VERSION ""

NS_ :

BS_:

BU_: DEVICE PC

BO_ 257 MA_THE_VA_TRANG_THAI: 6 DEVICE
 SG_ Ma_The_UID : 7|40@0+ (1,0) [0|0] "" PC
 SG_ Trang_Thai_Doc : 47|8@0+ (1,0) [0|1] "" PC

BO_ 258 BO_DEM: 4 DEVICE
 SG_ Dem_Hien_Tai : 7|16@0+ (1,0) [0|9999] "" PC
 SG_ Dem_Muc_Tieu : 23|16@0+ (1,0) [0|9999] "" PC

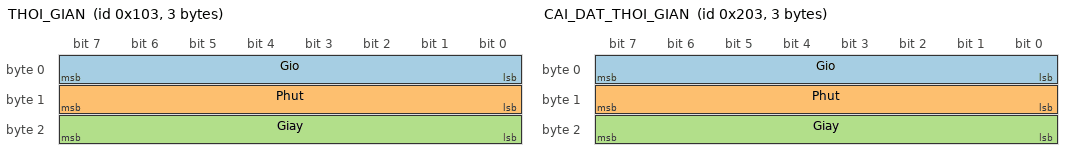
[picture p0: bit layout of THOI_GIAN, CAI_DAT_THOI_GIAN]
BO_ 259 THOI_GIAN: 3 DEVICE
 SG_ Gio : 7|8@0+ (1,0) [0|23] "" PC
 SG_ Phut : 15|8@0+ (1,0) [0|59] "" PC
 SG_ Giay : 23|8@0+ (1,0) [0|59] "" PC

BO_ 260 DU_LIEU_THE_P1: 8 DEVICE
 SG_ Du_Lieu_0_7 : 7|64@0+ (1,0) [0|0] "" PC

BO_ 261 DU_LIEU_THE_P2: 8 DEVICE
 SG_ Du_Lieu_8_15 : 7|64@0+ (1,0) [0|0] "" PC

BO_ 292 THONG_SO_CAM_BIEN: 8 DEVICE
 SG_ Tgian_Block_ms : 7|32@0+ (1,0) [0|0] "" PC
 SG_ Tgian_Gap_ms : 39|32@0+ (1,0) [0|0] "" PC

BO_ 293 THONG_SO_THE_SD: 4 DEVICE
 SG_ Tgian_Mount_ms : 7|32@0+ (1,0) [0|0] "" PC

BO_ 513 CAI_DAT_MUC_TIEU: 2 PC
 SG_ Muc_Tieu : 7|16@0+ (1,0) [0|9999] "" DEVICE

BO_ 514 CAI_DAT_DEM_HT: 2 PC
 SG_ Dem_Hien_Tai : 7|16@0+ (1,0) [0|9999] "" DEVICE

BO_ 515 CAI_DAT_THOI_GIAN: 3 PC
 SG_ Gio : 7|8@0+ (1,0) [0|23] "" DEVICE
 SG_ Phut : 15|8@0+ (1,0) [0|59] "" DEVICE
 SG_ Giay : 23|8@0+ (1,0) [0|59] "" DEVICE

BO_ 516 CAI_DAT_CN_THE: 1 PC
 SG_ Chuc_Nang : 7|8@0+ (1,0) [1|4] "" DEVICE

BO_ 517 QUAN_LY_THE: 7 PC
 SG_ Hanh_Dong : 7|8@0+ (1,0) [0|1] "" DEVICE
 SG_ Mat_Khau_Moi : 15|48@0+ (1,0) [0|0] "" DEVICE

BO_ 518 CAI_MAT_KHAU_TAM: 6 PC
 SG_ Mat_Khau_Tam : 7|48@0+ (1,0) [0|0] "" DEVICE

VAL_ 257 Trang_Thai_Doc 0 "Thanh Cong" 1 "That Bai" ;
VAL_ 516 Chuc_Nang 1 "Cong 1" 2 "Tru 1" 3 "Reset" 4 "Phat Nhac" ;
VAL_ 517 Hanh_Dong 0 "Xoa the" 1 "oi Key" ;
CM_ BO_ 257 "Ma the va Trang thai doc";
CM_ SG_ 257 Ma_The_UID "Ma UID cua the RFID";
CM_ SG_ 257 Trang_Thai_Doc "Trang thai doc the";

CM_ BO_ 258 "Bo dem san pham";
CM_ SG_ 258 Dem_Hien_Tai "So dem hien tai";
CM_ SG_ 258 Dem_Muc_Tieu "So dem muc tieu";

CM_ BO_ 259 "Thoi gian he thong";
CM_ SG_ 259 Gio "Gio";
CM_ SG_ 259 Phut "Phut";
CM_ SG_ 259 Giay "Giay";

CM_ BO_ 260 "Du lieu doc tu the (Phan 1)";
CM_ SG_ 260 Du_Lieu_0_7 "8 byte du lieu dau";

CM_ BO_ 261 "Du lieu doc tu the (Phan 2)";
CM_ SG_ 261 Du_Lieu_8_15 "8 byte du lieu sau";

CM_ BO_ 292 "Thong so chan doan cam bien";
CM_ SG_ 292 Tgian_Block_ms "Thoi gian bi che (ms)";
CM_ SG_ 292 Tgian_Gap_ms "Thoi gian ho (ms)";

CM_ BO_ 293 "Thong so chan doan the SD";
CM_ SG_ 293 Tgian_Mount_ms "Thoi gian Mount the (ms)";

CM_ BO_ 513 "Cai dat so dem muc tieu";
CM_ SG_ 513 Muc_Tieu "Gia tri muc tieu moi";

CM_ BO_ 514 "Cai dat so dem hien tai";
CM_ SG_ 514 Dem_Hien_Tai "Gia tri dem hien tai moi";

CM_ BO_ 515 "Cai dat thoi gian he thong";
CM_ SG_ 515 Gio "Gio moi";
CM_ SG_ 515 Phut "Phut moi";
CM_ SG_ 515 Giay "Giay moi";

CM_ BO_ 516 "Cai dat chuc nang the RFID";
CM_ SG_ 516 Chuc_Nang "Chuc nang gan cho the";

CM_ BO_ 517 "Xoa the hoac Doi mat khau";
CM_ SG_ 517 Hanh_Dong "Hanh dong muon thuc hien";
CM_ SG_ 517 Mat_Khau_Moi "Mat khau moi (neu co)";

CM_ BO_ 518 "Cai dat mat khau tam thoi";
CM_ SG_ 518 Mat_Khau_Tam "Mat khau dung 1 lan";
